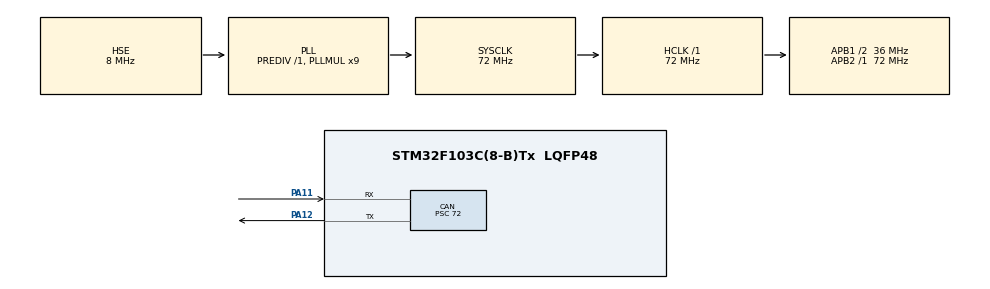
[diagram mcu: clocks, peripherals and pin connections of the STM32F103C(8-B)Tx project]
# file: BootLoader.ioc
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CAN.ABOM=ENABLE
CAN.BS1=CAN_BS1_8TQ
CAN.CalculateBaudRate=50000
CAN.CalculateTimeBit=20000
CAN.CalculateTimeQuantum=2000.0
CAN.Prescaler=72
CAN.SJW=CAN_SJW_2TQ
Mcu.Family=STM32F1
Mcu.Name=STM32F103C(8-B)Tx
Mcu.Package=LQFP48
NVIC.PriorityGroup=NVIC_PRIORITYGROUP_4
PA11.Mode=CAN_Activate
PA11.Signal=CAN_RX
PA12.Mode=CAN_Activate
PA12.Signal=CAN_TX
PA13.Mode=Serial_Wire
PA13.Signal=SYS_JTMS-SWDIO
PA14.Mode=Serial_Wire
PA14.Signal=SYS_JTCK-SWCLK
PD0-OSC_IN.Mode=HSE-External-Oscillator
PD0-OSC_IN.Signal=RCC_OSC_IN
PD1-OSC_OUT.Mode=HSE-External-Oscillator
PD1-OSC_OUT.Signal=RCC_OSC_OUT
ProjectManager.HeapSize=0x200
ProjectManager.StackSize=0x400
ProjectManager.TargetToolchain=CMake
RCC.AHBFreq_Value=72000000
RCC.APB1CLKDivider=RCC_HCLK_DIV2
RCC.APB1Freq_Value=36000000
RCC.APB1TimFreq_Value=72000000
RCC.APB2Freq_Value=72000000
RCC.APB2TimFreq_Value=72000000
RCC.HCLKFreq_Value=72000000
RCC.PLLMUL=RCC_PLL_MUL9
RCC.PLLSourceVirtual=RCC_PLLSOURCE_HSE
RCC.SYSCLKFreq_VALUE=72000000
RCC.SYSCLKSource=RCC_SYSCLKSOURCE_PLLCLK
RCC.USBFreq_Value=72000000
board=custom

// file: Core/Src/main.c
/* USER CODE BEGIN Header */
/**
 ******************************************************************************
 * @file           : main.c
 * @brief          : Main program body
 ******************************************************************************
 * @attention
 *
 * Copyright (c) 2026 STMicroelectronics.
 * All rights reserved.
 *
 * This software is licensed under terms that can be found in the LICENSE file
 * in the root directory of this software component.
 * If no LICENSE file comes with this software, it is provided AS-IS.
 *
 ******************************************************************************
 */
/* USER CODE END Header */
#include "main.h"
#include "can.h"
#include "gpio.h"

/* USER CODE BEGIN Includes */
#include "BootLoader.h"
/* USER CODE END Includes */

void SystemClock_Config(void);

/* USER CODE BEGIN 0 */

static void BoardLed_Init(void)
{
  GPIO_InitTypeDef GPIO_InitStruct = {0};

  __HAL_RCC_GPIOC_CLK_ENABLE();
  HAL_GPIO_WritePin(GPIOC, GPIO_PIN_13, GPIO_PIN_RESET);
  GPIO_InitStruct.Pin = GPIO_PIN_13;
  GPIO_InitStruct.Mode = GPIO_MODE_OUTPUT_PP;
  GPIO_InitStruct.Pull = GPIO_NOPULL;
  GPIO_InitStruct.Speed = GPIO_SPEED_FREQ_LOW;
  HAL_GPIO_Init(GPIOC, &GPIO_InitStruct);
}

/* USER CODE END 0 */

int main(void)
{

  /* MCU Configuration--------------------------------------------------------*/

  /* Reset of all peripherals, Initializes the Flash interface and the Systick. */
  HAL_Init();

  /* Configure the system clock */
  SystemClock_Config();

  /* Initialize all configured peripherals */
  MX_GPIO_Init();
  BoardLed_Init();
  MX_CAN_Init();
  CAN_IAP_Init();
  /* USER CODE BEGIN 2 */
  /* CAN-only BootLoader：无 IAP 标志时给应用 3 秒启动窗口。 */
  uint32_t boot_tick = HAL_GetTick();
  uint32_t led_tick = boot_tick;
  /* USER CODE END 2 */

  /* Infinite loop */
  /* USER CODE BEGIN WHILE */
  while (1) {
    CAN_IAP_Process();
    if ((HAL_GetTick() - led_tick) >= 500U) {
      HAL_GPIO_TogglePin(GPIOC, GPIO_PIN_13);
      led_tick = HAL_GetTick();
    }
    if (CAN_IAP_IsActive() == 0U && (HAL_GetTick() - boot_tick) >= 3000U) {
      BootLoader_JumpToApp();
    }
    HAL_Delay(1U);
  }
  /* USER CODE END 3 */
}

void SystemClock_Config(void)
{
  RCC_OscInitTypeDef RCC_OscInitStruct = {0};
  RCC_ClkInitTypeDef RCC_ClkInitStruct = {0};

  /** Initializes the RCC Oscillators according to the specified parameters
  * in the RCC_OscInitTypeDef structure.
  */
  RCC_OscInitStruct.OscillatorType = RCC_OSCILLATORTYPE_HSE;
  RCC_OscInitStruct.HSEState = RCC_HSE_ON;
  RCC_OscInitStruct.HSEPredivValue = RCC_HSE_PREDIV_DIV1;
  RCC_OscInitStruct.HSIState = RCC_HSI_ON;
  RCC_OscInitStruct.PLL.PLLState = RCC_PLL_ON;
  RCC_OscInitStruct.PLL.PLLSource = RCC_PLLSOURCE_HSE;
  RCC_OscInitStruct.PLL.PLLMUL = RCC_PLL_MUL9;
  if (HAL_RCC_OscConfig(&RCC_OscInitStruct) != HAL_OK)
  {
    Error_Handler();
  }

  /** Initializes the CPU, AHB and APB buses clocks
  */
  RCC_ClkInitStruct.ClockType = RCC_CLOCKTYPE_HCLK|RCC_CLOCKTYPE_SYSCLK
                              |RCC_CLOCKTYPE_PCLK1|RCC_CLOCKTYPE_PCLK2;
  RCC_ClkInitStruct.SYSCLKSource = RCC_SYSCLKSOURCE_PLLCLK;
  RCC_ClkInitStruct.AHBCLKDivider = RCC_SYSCLK_DIV1;
  RCC_ClkInitStruct.APB1CLKDivider = RCC_HCLK_DIV2;
  RCC_ClkInitStruct.APB2CLKDivider = RCC_HCLK_DIV1;

  if (HAL_RCC_ClockConfig(&RCC_ClkInitStruct, FLASH_LATENCY_2) != HAL_OK)
  {
    Error_Handler();
  }
}

void Error_Handler(void)
{
  __disable_irq();
  while (1) {
  }
}
#ifdef USE_FULL_ASSERT
/**
  * @brief  Reports the name of the source file and the source line number
  *         where the assert_param error has occurred.
  * @param  file: pointer to the source file name
  * @param  line: assert_param error line source number
  * @retval None
  */
void assert_failed(uint8_t *file, uint32_t line)
{
  /* USER CODE BEGIN 6 */
  /* User can add his own implementation to report the file name and line
     number, ex: printf("Wrong parameters value: file %s on line %d\r\n", file,
     line) */
  /* USER CODE END 6 */
}
#endif /* USE_FULL_ASSERT */
